# ATmega256RFR2 register map
Vendor: Atmel; File version: 1.0
CPU: other r0p0, little endian, no MPU, no FPU, 4 interrupt priority bits
Registers are 8-bit, read-write, reset 0x0 unless marked. A register's access mark holds for its fields unless they carry their own. Offsets are from the block's base; [hi:lo] are bit positions; {n}, {i} and the like mark numbered series.

## AC — Analog Comparator
Base 0x00800050
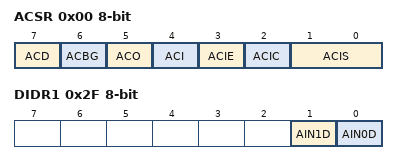
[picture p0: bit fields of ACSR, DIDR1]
0x00 ACSR — Analog Comparator Control And Status Register
  [7] ACD — Analog Comparator Disable
  [6] ACBG — Analog Comparator Bandgap Select
  [5] ACO — Analog Compare Output
  [4] ACI — Analog Comparator Interrupt Flag
  [3] ACIE — Analog Comparator Interrupt Enable
  [2] ACIC — Analog Comparator Input Capture Enable
  [1:0] ACIS — Analog Comparator Interrupt Mode Select
    0=INTERRUPT_ON_TOGGLE; 2=INTERRUPT_ON_FALLING_EDGE; 3=INTERRUPT_ON_RISING_EDGE
0x2B ADCSRB — ADC Control and Status Register B
  [6] ACME — Analog Comparator Multiplexer Enable
0x2F DIDR1 — Digital Input Disable Register 1
  [1] AIN1D — AIN1 Digital Input Disable
  [0] AIN0D — AIN0 Digital Input Disable

## ADC — Analog-to-Digital Converter
Base 0x00800077
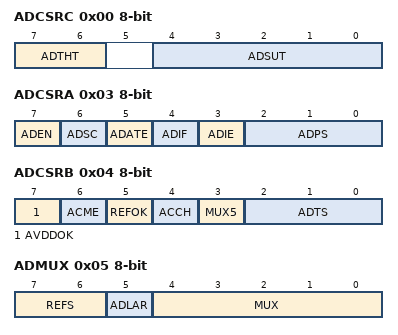
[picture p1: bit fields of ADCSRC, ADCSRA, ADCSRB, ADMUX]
0x00 ADCSRC — The ADC Control and Status Register C
  [7:6] ADTHT — ADC Track-and-Hold Time
    0=SINGLE_ENDED_1_DIFFERENTIAL_3_ADC_CLOCK_CYCLES; 1=SINGLE_ENDED_2_DIFFERENTIAL_5_ADC_CLOCK_CYCLES; 2=SINGLE_ENDED_3_DIFFERENTIAL_7_ADC_CLOCK_CYCLES; 3=SINGLE_ENDED_4_DIFFERENTIAL_9_ADC_CLOCK_CYCLES
  [4:0] ADSUT — ADC Start-up Time
    0=3_ADC_CLOCK_CYCLES; 1=7_ADC_CLOCK_CYCLES; 2=11_ADC_CLOCK_CYCLES; 3=15_ADC_CLOCK_CYCLES
0x01 ADC 16-bit (reset mask 0xFF) — ADC Data Register Bytes
0x03 ADCSRA — The ADC Control and Status Register A
  [7] ADEN — ADC Enable
  [6] ADSC — ADC Start Conversion
  [5] ADATE — ADC Auto Trigger Enable
  [4] ADIF — ADC Interrupt Flag
  [3] ADIE — ADC Interrupt Enable
  [2:0] ADPS — ADC Prescaler Select Bits
    1=2; 2=4; 3=8; 4=16; 5=32; 6=64; 7=128
0x04 ADCSRB — The ADC Control and Status Register B
  [7] AVDDOK — AVDD Supply Voltage OK
  [6] ACME — Analog Comparator Multiplexer Enable
  [5] REFOK — Reference Voltage OK
  [4] ACCH — Analog Channel Change
  [3] MUX5 — Analog Channel and Gain Selection Bits
  [2:0] ADTS — ADC Auto Trigger Source
    0=FREE_RUNNING_MODE; 1=ANALOG_COMPARATOR; 2=EXTERNAL_INTERRUPT_REQUEST_0; 3=TIMER_COUNTER0_COMPARE_MATCH_A; 4=TIMER_COUNTER0_OVERFLOW; 5=TIMER_COUNTER1_COMPARE_MATCH_B; 6=TIMER_COUNTER1_OVERFLOW; 7=TIMER_COUNTER1_CAPTURE_EVENT
0x05 ADMUX — The ADC Multiplexer Selection Register
  [7:6] REFS — Reference Selection Bits
    0=AREF_INTERNAL_REFERENCE_VOLTAGE_GENERATION_TURNED_OFF; 1=AVDD_WITH_EXTERNAL_CAPACITOR_AT_AREF_PIN; 2=INTERNAL_1_5V_VOLTAGE_REFERENCE_NO_EXTERNAL_CAPACITOR_AT_AREF_PIN; 3=INTERNAL_1_6V_VOLTAGE_REFERENCE_NO_EXTERNAL_CAPACITOR_AT_AREF_PIN
  [5] ADLAR — ADC Left Adjust Result
  [4:0] MUX — Analog Channel and Gain Selection Bits
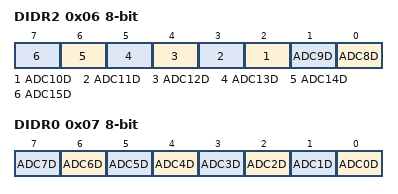
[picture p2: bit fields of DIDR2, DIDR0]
0x06 DIDR2 — Digital Input Disable Register 2
  [n-8] ADC{n}D (n=8..15) — Reserved Bits
0x07 DIDR0 — Digital Input Disable Register 0
  [n] ADC{n}D (n=0..7) — Disable ADC7:0 Digital Input

## BOOT_LOAD — Bootloader
Base 0x00800057
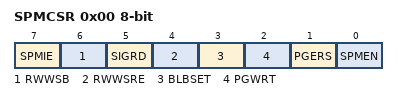
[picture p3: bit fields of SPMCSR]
0x00 SPMCSR — Store Program Memory Control Register
  [7] SPMIE — SPM Interrupt Enable
  [6] RWWSB — Read While Write Section Busy
  [5] SIGRD — Signature Row Read
  [4] RWWSRE — Read While Write Section Read Enable
  [3] BLBSET — Boot Lock Bit Set
  [2] PGWRT — Page Write
  [1] PGERS — Page Erase
  [0] SPMEN — Store Program Memory Enable

## CPU — CPU Registers
Base 0x0080003E
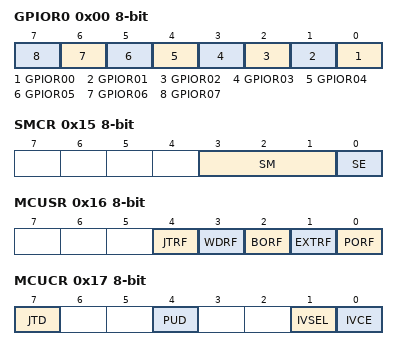
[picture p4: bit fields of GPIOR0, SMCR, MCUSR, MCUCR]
0x00 GPIOR0 — General Purpose IO Register 0
  [n] GPIOR{n:02} (n=0..7) — General Purpose I/O Register 0 Value
0x0C GPIOR1 — General Purpose IO Register 1
  [7:0] GPIOR — General Purpose I/O Register 1 Value
0x0D GPIOR2 — General Purpose I/O Register 2
  [7:0] GPIOR — General Purpose I/O Register 2 Value
0x15 SMCR — Sleep Mode Control Register
  [3:1] SM — Sleep Mode Select bits
    0=IDLE; 1=ADC (ADC Noise Reduction (If Available)); 2=PDOWN (Power Down); 3=PSAVE (Power Save); 6=STDBY (Standby); 7=ESTDBY (Extended Standby)
  [0] SE — Sleep Enable
0x16 MCUSR — MCU Status Register
  [4] JTRF — JTAG Reset Flag
  [3] WDRF — Watchdog Reset Flag
  [2] BORF — Brown-out Reset Flag
  [1] EXTRF — External Reset Flag
  [0] PORF — Power-on Reset Flag
0x17 MCUCR — MCU Control Register
  [7] JTD — JTAG Interface Disable
  [4] PUD — Pull-up Disable
  [1] IVSEL — Interrupt Vector Select
  [0] IVCE — Interrupt Vector Change Enable
0x1D RAMPZ — Extended Z-pointer Register for ELPM/SPM
  [1:0] RAMPZ — Extended Z-Pointer Value
    0=DEFAULT_VALUE_OF_Z_POINTER_MSB_S
0x1E EIND — Extended Indirect Register
0x1F SP 16-bit (reset mask 0xFF) — Stack Pointer
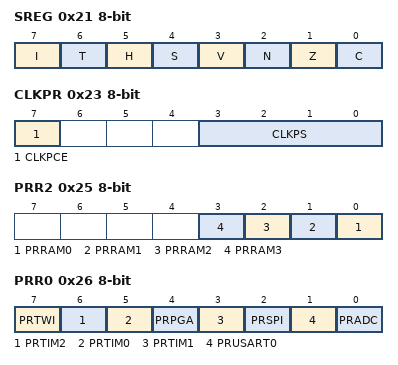
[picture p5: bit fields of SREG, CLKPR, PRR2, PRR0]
0x21 SREG — Status Register
  [7] I — Global Interrupt Enable
  [6] T — Bit Copy Storage
  [5] H — Half Carry Flag
  [4] S — Sign Bit
  [3] V — Two's Complement Overflow Flag
  [2] N — Negative Flag
  [1] Z — Zero Flag
  [0] C — Carry Flag
0x23 CLKPR — Clock Prescale Register (read-only for debugger)
  [7] CLKPCE — Clock Prescaler Change Enable
  [3:0] CLKPS — Clock Prescaler Select Bits
    0=DIVISION_FACTOR_1_RC_OSCILLATOR_2; 1=DIVISION_FACTOR_2_RC_OSCILLATOR_4; 2=DIVISION_FACTOR_4_RC_OSCILLATOR_8; 3=DIVISION_FACTOR_8_RC_OSCILLATOR_16; 4=DIVISION_FACTOR_16_RC_OSCILLATOR_32; 5=DIVISION_FACTOR_32_RC_OSCILLATOR_64; 6=DIVISION_FACTOR_64_RC_OSCILLATOR_128; 7=DIVISION_FACTOR_128_RC_OSCILLATOR_256; 8=DIVISION_FACTOR_256_RC_OSCILLATOR_512; 15=DIVISION_FACTOR_1_ONLY_PERMITTED_FOR_RC_OSCILLATOR_FLASH_AND_EEPROM_PROGRAMMING_IS_NOT_ALLOWED
0x25 PRR2 — Power Reduction Register 2
  [n] PRRAM{n} (n=0..3) — Power Reduction SRAM{n}
0x26 PRR0 — Power Reduction Register0
  [7] PRTWI — Power Reduction TWI
  [6] PRTIM2 — Power Reduction Timer/Counter2
  [5] PRTIM0 — Power Reduction Timer/Counter0
  [4] PRPGA — Power Reduction PGA
  [3] PRTIM1 — Power Reduction Timer/Counter1
  [2] PRSPI — Power Reduction Serial Peripheral Interface
  [1] PRUSART0 — Power Reduction USART
  [0] PRADC — Power Reduction ADC
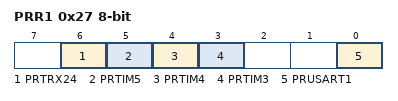
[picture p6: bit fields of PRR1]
0x27 PRR1 — Power Reduction Register 1
  [6] PRTRX24 — Power Reduction Transceiver
  [5] PRTIM5 — Power Reduction Timer/Counter5
  [4] PRTIM4 — Power Reduction Timer/Counter4
  [3] PRTIM3 — Power Reduction Timer/Counter3
  [0] PRUSART1 — Power Reduction USART1
0x28 OSCCAL — Oscillator Calibration Value
  [7:0] CAL — Oscillator Calibration Tuning Value
    0=CALIBRATION_VALUE_FOR_LOWEST_OSCILLATOR_FREQUENCY; 127=END_VALUE_OF_LOW_FREQUENCY_RANGE_CALIBRATION; 128=START_VALUE_OF_HIGH_FREQUENCY_RANGE_CALIBRATION; 255=CALIBRATION_VALUE_FOR_HIGHEST_OSCILLATOR_FREQUENCY
  [7:0] OSCCAL — Oscillator Calibration
